# STM32L011D3P6 register map
File version: 1.0
Registers are 32-bit, access not given, reset 0x0 unless marked. A register's access mark holds for its fields unless they carry their own. Offsets are from the block's base; [hi:lo] are bit positions; {n}, {i} and the like mark numbered series.

## LPUART1
Base 0x40004800
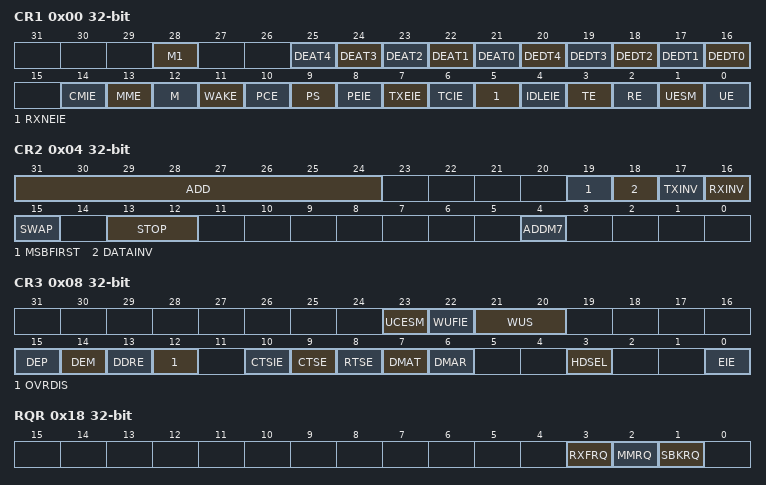
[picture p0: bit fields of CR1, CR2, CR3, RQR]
0x00 CR1
  [28] M1, [n+21] DEAT{n} (n=0..4), [n+16] DEDT{n} (n=0..4), [14] CMIE, [13] MME, [12] M, [11] WAKE, [10] PCE, [9] PS, [8] PEIE, [7] TXEIE, [6] TCIE, [5] RXNEIE, [4] IDLEIE, [3] TE, [2] RE, [1] UESM, [0] UE
0x04 CR2
  [31:24] ADD, [19] MSBFIRST, [18] DATAINV, [17] TXINV, [16] RXINV, [15] SWAP, [13:12] STOP, [4] ADDM7
0x08 CR3
  [23] UCESM, [22] WUFIE, [21:20] WUS, [15] DEP, [14] DEM, [13] DDRE, [12] OVRDIS, [10] CTSIE, [9] CTSE, [8] RTSE, [7] DMAT, [6] DMAR, [3] HDSEL, [0] EIE
0x0C BRR
  [19:0] BRR
0x18 RQR
  [3] RXFRQ, [2] MMRQ, [1] SBKRQ
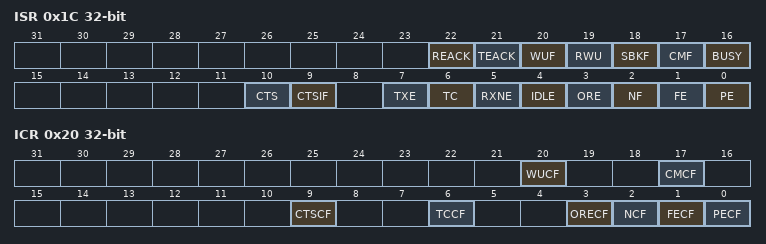
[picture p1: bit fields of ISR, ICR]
0x1C ISR
  [22] REACK, [21] TEACK, [20] WUF, [19] RWU, [18] SBKF, [17] CMF, [16] BUSY, [10] CTS, [9] CTSIF, [7] TXE, [6] TC, [5] RXNE, [4] IDLE, [3] ORE, [2] NF, [1] FE, [0] PE
0x20 ICR
  [20] WUCF, [17] CMCF, [9] CTSCF, [6] TCCF, [3] ORECF, [2] NCF, [1] FECF, [0] PECF
0x24 RDR
  [8:0] RDR
0x28 TDR
  [8:0] TDR

## I2C1
Base 0x40005400
Same registers: I2C2 0x40005800, I2C3 0x40007800
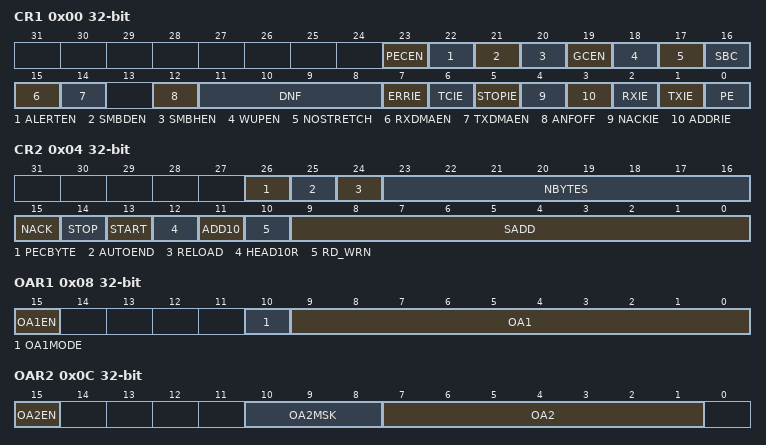
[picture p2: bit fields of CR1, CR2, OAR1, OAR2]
0x00 CR1
  [23] PECEN, [22] ALERTEN, [21] SMBDEN, [20] SMBHEN, [19] GCEN, [18] WUPEN, [17] NOSTRETCH, [16] SBC, [15] RXDMAEN, [14] TXDMAEN, [12] ANFOFF, [11:8] DNF, [7] ERRIE, [6] TCIE, [5] STOPIE, [4] NACKIE, [3] ADDRIE, [2] RXIE, [1] TXIE, [0] PE
0x04 CR2
  [26] PECBYTE, [25] AUTOEND, [24] RELOAD, [23:16] NBYTES, [15] NACK, [14] STOP, [13] START, [12] HEAD10R, [11] ADD10, [10] RD_WRN, [9:0] SADD
0x08 OAR1
  [15] OA1EN, [10] OA1MODE, [9:0] OA1
0x0C OAR2
  [15] OA2EN, [10:8] OA2MSK, [7:1] OA2
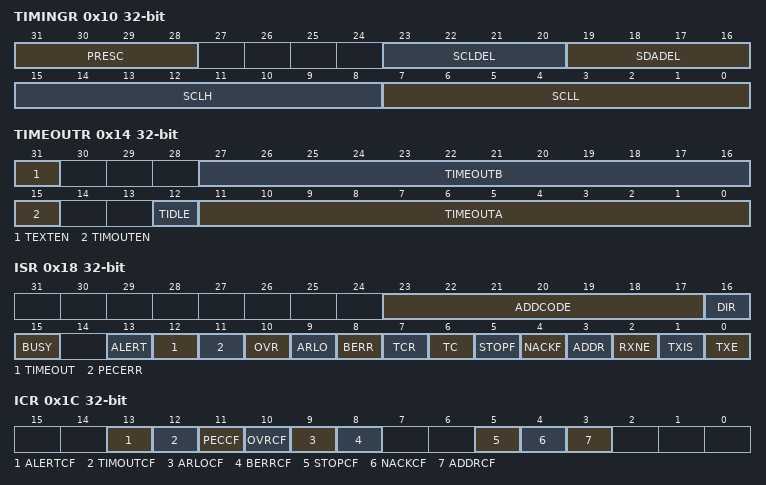
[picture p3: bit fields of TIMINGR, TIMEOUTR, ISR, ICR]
0x10 TIMINGR
  [31:28] PRESC, [23:20] SCLDEL, [19:16] SDADEL, [15:8] SCLH, [7:0] SCLL
0x14 TIMEOUTR
  [31] TEXTEN, [27:16] TIMEOUTB, [15] TIMOUTEN, [12] TIDLE, [11:0] TIMEOUTA
0x18 ISR
  [23:17] ADDCODE, [16] DIR, [15] BUSY, [13] ALERT, [12] TIMEOUT, [11] PECERR, [10] OVR, [9] ARLO, [8] BERR, [7] TCR, [6] TC, [5] STOPF, [4] NACKF, [3] ADDR, [2] RXNE, [1] TXIS, [0] TXE
0x1C ICR
  [13] ALERTCF, [12] TIMOUTCF, [11] PECCF, [10] OVRCF, [9] ARLOCF, [8] BERRCF, [5] STOPCF, [4] NACKCF, [3] ADDRCF
0x20 PECR
  [7:0] PEC
0x24 RXDR
  [7:0] RXDATA
0x28 TXDR
  [7:0] TXDATA

## PWR
Base 0x40007000
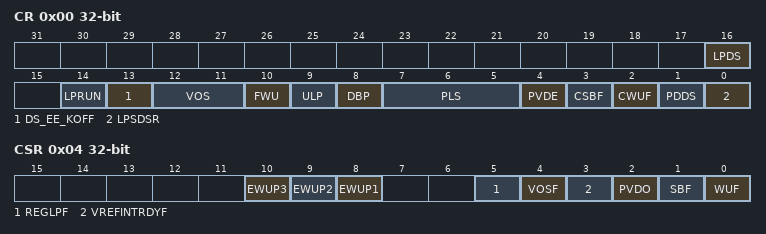
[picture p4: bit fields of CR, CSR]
0x00 CR
  [16] LPDS, [14] LPRUN, [13] DS_EE_KOFF, [12:11] VOS, [10] FWU, [9] ULP, [8] DBP, [7:5] PLS, [4] PVDE, [3] CSBF, [2] CWUF, [1] PDDS, [0] LPSDSR
0x04 CSR
  [10] EWUP3, [9] EWUP2, [8] EWUP1, [5] REGLPF, [4] VOSF, [3] VREFINTRDYF, [2] PVDO, [1] SBF, [0] WUF

## LPTIM1
Base 0x40007C00
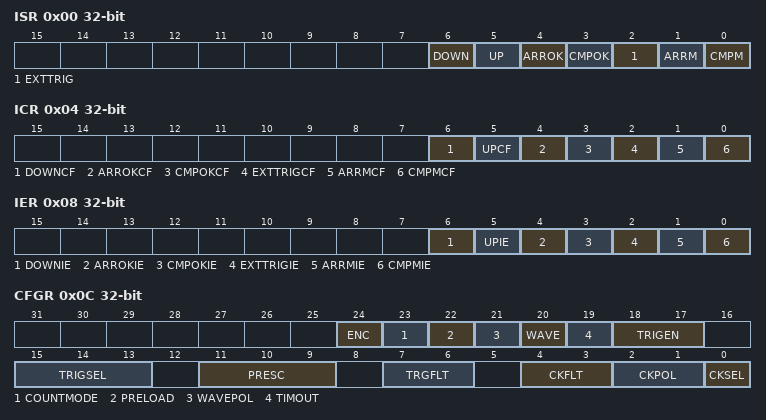
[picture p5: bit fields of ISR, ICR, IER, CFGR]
0x00 ISR
  [6] DOWN, [5] UP, [4] ARROK, [3] CMPOK, [2] EXTTRIG, [1] ARRM, [0] CMPM
0x04 ICR
  [6] DOWNCF, [5] UPCF, [4] ARROKCF, [3] CMPOKCF, [2] EXTTRIGCF, [1] ARRMCF, [0] CMPMCF
0x08 IER
  [6] DOWNIE, [5] UPIE, [4] ARROKIE, [3] CMPOKIE, [2] EXTTRIGIE, [1] ARRMIE, [0] CMPMIE
0x0C CFGR
  [24] ENC, [23] COUNTMODE, [22] PRELOAD, [21] WAVEPOL, [20] WAVE, [19] TIMOUT, [18:17] TRIGEN, [15:13] TRIGSEL, [11:9] PRESC, [7:6] TRGFLT, [4:3] CKFLT, [2:1] CKPOL, [0] CKSEL
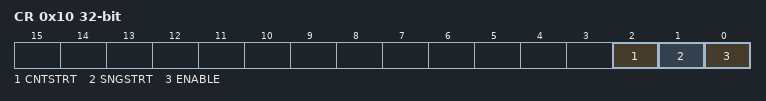
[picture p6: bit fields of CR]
0x10 CR
  [2] CNTSTRT, [1] SNGSTRT, [0] ENABLE
0x14 CMP
  [15:0] CMP
0x18 ARR
  [15:0] ARR
0x1C CNT
  [15:0] CNT

## COMP
Base 0x40010000
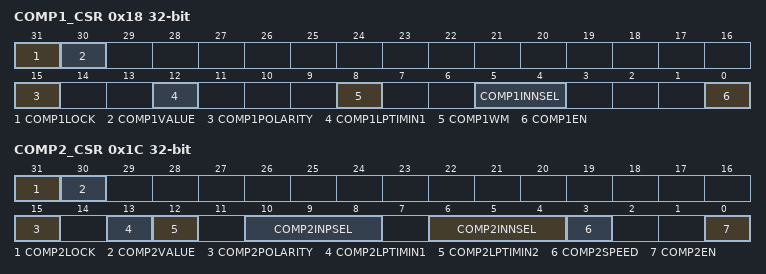
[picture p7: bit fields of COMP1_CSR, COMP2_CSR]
0x18 COMP1_CSR
  [31] COMP1LOCK, [30] COMP1VALUE, [15] COMP1POLARITY, [12] COMP1LPTIMIN1, [8] COMP1WM, [5:4] COMP1INNSEL, [0] COMP1EN
0x1C COMP2_CSR
  [31] COMP2LOCK, [30] COMP2VALUE, [15] COMP2POLARITY, [13] COMP2LPTIMIN1, [12] COMP2LPTIMIN2, [10:8] COMP2INPSEL, [6:4] COMP2INNSEL, [3] COMP2SPEED, [0] COMP2EN

## SYSCFG
Base 0x40010000
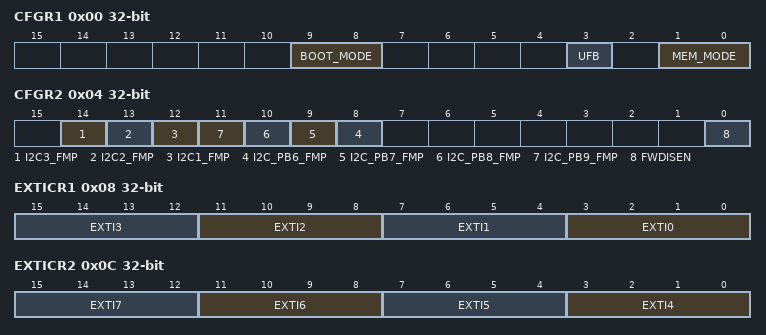
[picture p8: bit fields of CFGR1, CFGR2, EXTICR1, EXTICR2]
0x00 CFGR1
  [9:8] BOOT_MODE, [3] UFB, [1:0] MEM_MODE
0x04 CFGR2
  [14] I2C3_FMP, [13] I2C2_FMP, [12] I2C1_FMP, [n+2] I2C_PB{n}_FMP (n=6..9), [0] FWDISEN
0x08 EXTICR1
  [4n+3:4n] EXTI{n} (n=0..3)
0x0C EXTICR2
  [4n-13:4n-16] EXTI{n} (n=4..7)
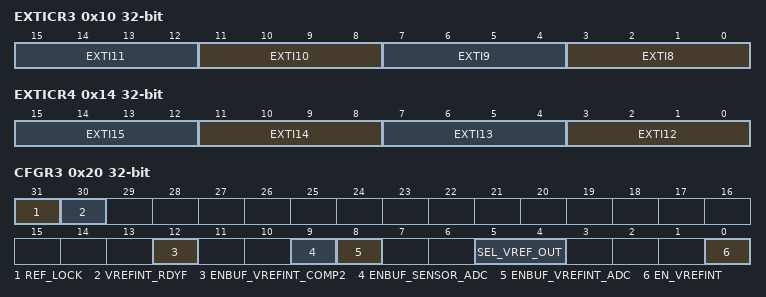
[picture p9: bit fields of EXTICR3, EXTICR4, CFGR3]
0x10 EXTICR3
  [4n-29:4n-32] EXTI{n} (n=8..11)
0x14 EXTICR4
  [4n-45:4n-48] EXTI{n} (n=12..15)
0x20 CFGR3
  [31] REF_LOCK, [30] VREFINT_RDYF, [12] ENBUF_VREFINT_COMP2, [9] ENBUF_SENSOR_ADC, [8] ENBUF_VREFINT_ADC, [5:4] SEL_VREF_OUT, [0] EN_VREFINT
